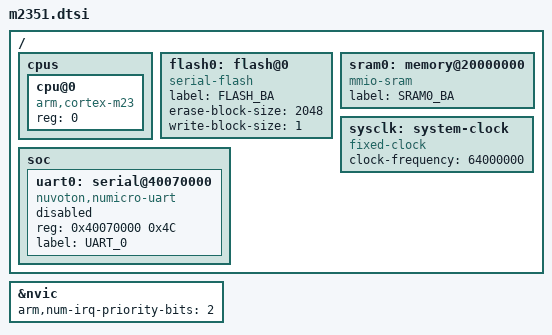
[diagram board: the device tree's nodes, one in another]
/* SPDX-License-Identifier: Apache-2.0 */

 #include <arm/armv8-m.dtsi>
 #include <mem.h>

/ {
	cpus {
		#address-cells = <1>;
		#size-cells = <0>;

		cpu@0 {
			device_type = "cpu";
			compatible = "arm,cortex-m23";
			reg = <0>;
		};
	};

	flash0: flash@0 {
		compatible = "serial-flash";
		label = "FLASH_BA";
		erase-block-size = <2048>;
		write-block-size = <1>;
	};

	sram0: memory@20000000 {
		compatible = "mmio-sram";
		label = "SRAM0_BA";
	};

	sysclk: system-clock {
		compatible = "fixed-clock";
		clock-frequency = <64000000>;
		// XXX: Not sure what this field is
		#clock-cells = <0>;
	};

	soc {
		uart0: serial@40070000 {
			compatible = "nuvoton,numicro-uart";
			// XXX: The datasheet says a uart registry is 0x4C in size, but the size listed in the other numicro is way larger.  Am I looking at the wrong thing?
			reg = <0x40070000 0x4C>;
			status = "disabled";
			label = "UART_0";
		};
	};
};

&nvic {
	// "A programmable priority level of 0-3 for each interrupt"
	arm,num-irq-priority-bits = <2>;
};
